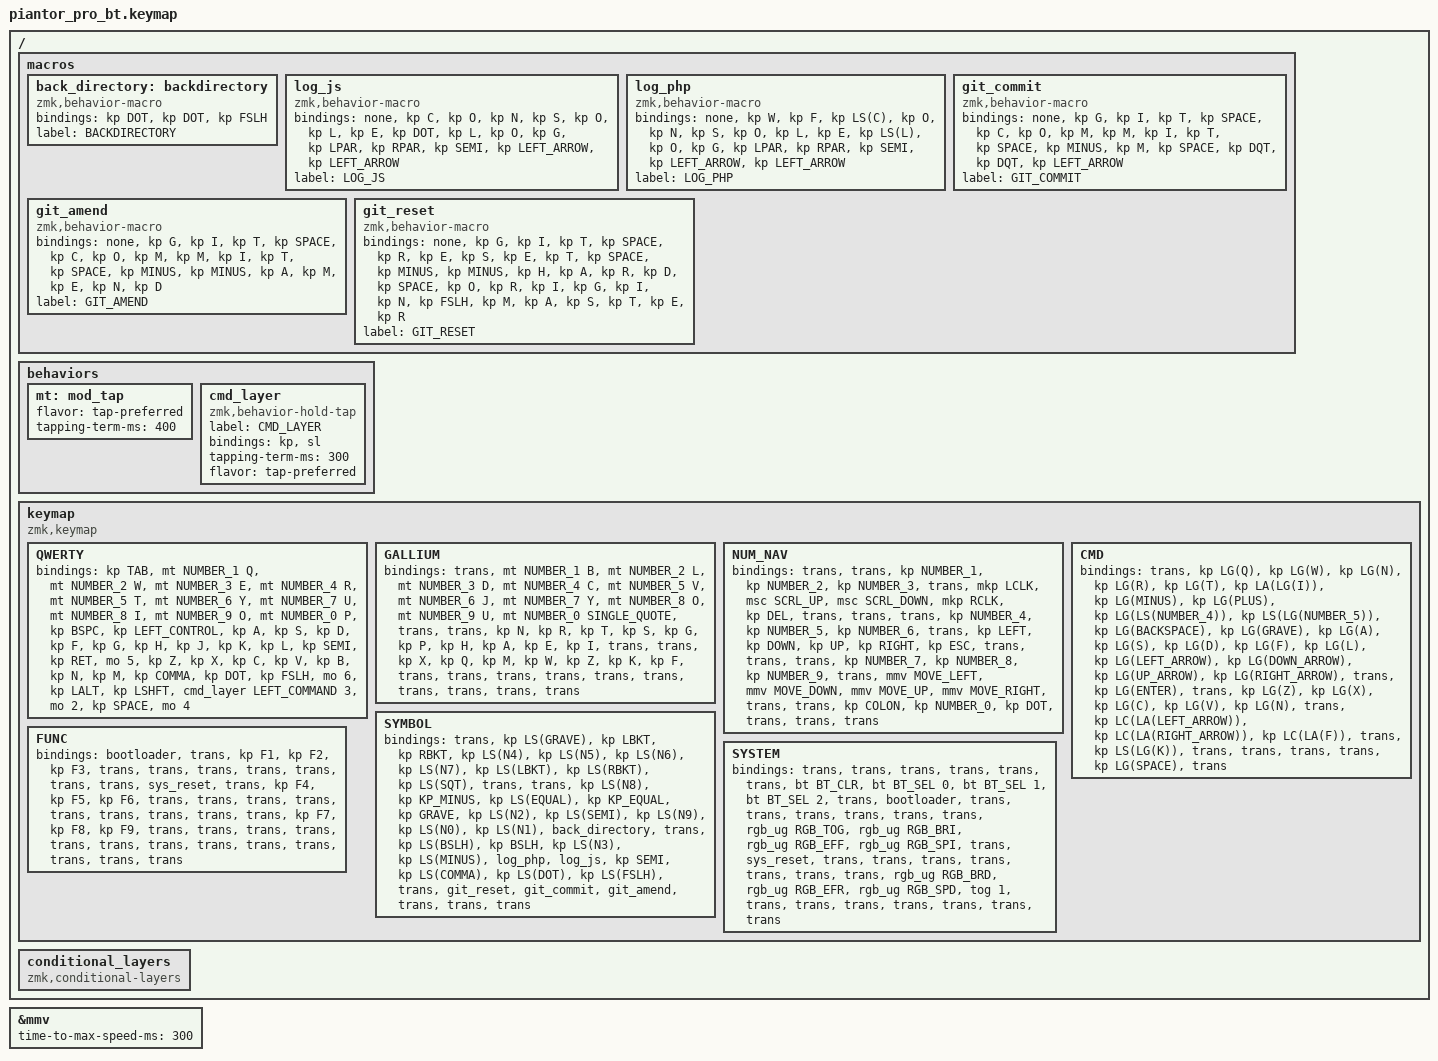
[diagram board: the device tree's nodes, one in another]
#define ZMK_POINTING_DEFAULT_MOVE_VAL 1500
#define ZMK_POINTING_DEFAULT_SCRL_VAL 15

#include <dt-bindings/zmk/behaviors.h>
#include <behaviors.dtsi>
#include <dt-bindings/zmk/bt.h>
#include <dt-bindings/zmk/keys.h>
#include <dt-bindings/zmk/pointing.h>
#include <dt-bindings/zmk/rgb.h>

&mt {
    tapping-term-ms = <400>;
    flavor = "tap-preferred";
};

&mmv { time-to-max-speed-ms = <300>; };

/ {
    macros {
        back_directory: backdirectory {
            compatible = "zmk,behavior-macro";
            #binding-cells = <0>;
            bindings = <&kp DOT &kp DOT &kp FSLH>;
            label = "BACKDIRECTORY";
        };

        log_js: log_js {
            compatible = "zmk,behavior-macro";
            #binding-cells = <0>;
            bindings = <&none &kp C &kp O &kp N &kp S &kp O &kp L &kp E &kp DOT &kp L &kp O &kp G &kp LPAR &kp RPAR &kp SEMI &kp LEFT_ARROW &kp LEFT_ARROW>;
            label = "LOG_JS";
        };

        log_php: log_php {
            compatible = "zmk,behavior-macro";
            #binding-cells = <0>;
            bindings = <&none &kp W &kp F &kp LS(C) &kp O &kp N &kp S &kp O &kp L &kp E &kp LS(L) &kp O &kp G &kp LPAR &kp RPAR &kp SEMI &kp LEFT_ARROW &kp LEFT_ARROW>;
            label = "LOG_PHP";
        };

        git_commit: git_commit {
            compatible = "zmk,behavior-macro";
            #binding-cells = <0>;
            bindings = <&none &kp G &kp I &kp T &kp SPACE &kp C &kp O &kp M &kp M &kp I &kp T &kp SPACE &kp MINUS &kp M &kp SPACE &kp DQT &kp DQT &kp LEFT_ARROW>;
            label = "GIT_COMMIT";
        };

        git_amend: git_amend {
            compatible = "zmk,behavior-macro";
            #binding-cells = <0>;
            bindings = <&none &kp G &kp I &kp T &kp SPACE &kp C &kp O &kp M &kp M &kp I &kp T &kp SPACE &kp MINUS &kp MINUS &kp A &kp M &kp E &kp N &kp D>;
            label = "GIT_AMEND";
        };

        git_reset: git_reset {
            compatible = "zmk,behavior-macro";
            #binding-cells = <0>;
            bindings = <&none &kp G &kp I &kp T &kp SPACE &kp R &kp E &kp S &kp E &kp T &kp SPACE &kp MINUS &kp MINUS &kp H &kp A &kp R &kp D &kp SPACE &kp O &kp R &kp I &kp G &kp I &kp N &kp FSLH &kp M &kp A &kp S &kp T &kp E &kp R>;
            label = "GIT_RESET";
        };
    };

    behaviors {
        mt: mod_tap {
            flavor = "tap-preferred";
            tapping-term-ms = <400>;
        };

        cmd_layer: cmd_layer {
            compatible = "zmk,behavior-hold-tap";
            label = "CMD_LAYER";
            bindings = <&kp>, <&sl>;

            #binding-cells = <2>;
            tapping-term-ms = <300>;
            flavor = "tap-preferred";
        };
    };

    keymap {
        compatible = "zmk,keymap";

        QWERTY {
            bindings = <
&kp TAB  &mt NUMBER_1 Q  &mt NUMBER_2 W  &mt NUMBER_3 E  &mt NUMBER_4 R  &mt NUMBER_5 T  &mt NUMBER_6 Y  &mt NUMBER_7 U  &mt NUMBER_8 I  &mt NUMBER_9 O  &mt NUMBER_0 P  &kp BSPC  &kp LEFT_CONTROL  &kp A  &kp S  &kp D  &kp F  &kp G  &kp H  &kp J  &kp K  &kp L  &kp SEMI  &kp RET  &mo 5  &kp Z  &kp X  &kp C  &kp V  &kp B  &kp N  &kp M  &kp COMMA  &kp DOT  &kp FSLH  &mo 6  &kp LALT  &kp LSHFT  &cmd_layer LEFT_COMMAND 3  &mo 2  &kp SPACE  &mo 4
            >;
        };

        GALLIUM {
            bindings = <
&trans  &mt NUMBER_1 B  &mt NUMBER_2 L  &mt NUMBER_3 D  &mt NUMBER_4 C  &mt NUMBER_5 V  &mt NUMBER_6 J  &mt NUMBER_7 Y  &mt NUMBER_8 O  &mt NUMBER_9 U  &mt NUMBER_0 SINGLE_QUOTE  &trans  &trans  &kp N  &kp R  &kp T  &kp S  &kp G  &kp P  &kp H  &kp A  &kp E  &kp I  &trans  &trans  &kp X  &kp Q  &kp M  &kp W  &kp Z  &kp K  &kp F  &trans  &trans  &trans  &trans  &trans  &trans  &trans  &trans  &trans  &trans
            >;
        };

        NUM_NAV {
            bindings = <
&trans  &trans  &kp NUMBER_1  &kp NUMBER_2  &kp NUMBER_3  &trans  &mkp LCLK  &msc SCRL_UP  &msc SCRL_DOWN  &mkp RCLK  &kp DEL  &trans  &trans  &trans  &kp NUMBER_4  &kp NUMBER_5  &kp NUMBER_6  &trans  &kp LEFT  &kp DOWN  &kp UP  &kp RIGHT  &kp ESC  &trans  &trans  &trans  &kp NUMBER_7  &kp NUMBER_8  &kp NUMBER_9  &trans  &mmv MOVE_LEFT  &mmv MOVE_DOWN  &mmv MOVE_UP  &mmv MOVE_RIGHT  &trans  &trans  &kp COLON  &kp NUMBER_0  &kp DOT  &trans  &trans  &trans
            >;
        };

        CMD {
            bindings = <
&trans  &kp LG(Q)  &kp LG(W)  &kp LG(N)  &kp LG(R)  &kp LG(T)  &kp LA(LG(I))  &kp LG(MINUS)  &kp LG(PLUS)  &kp LG(LS(NUMBER_4))  &kp LS(LG(NUMBER_5))  &kp LG(BACKSPACE)  &kp LG(GRAVE)  &kp LG(A)  &kp LG(S)  &kp LG(D)  &kp LG(F)  &kp LG(L)  &kp LG(LEFT_ARROW)  &kp LG(DOWN_ARROW)  &kp LG(UP_ARROW)  &kp LG(RIGHT_ARROW)  &trans  &kp LG(ENTER)  &trans  &kp LG(Z)  &kp LG(X)  &kp LG(C)  &kp LG(V)  &kp LG(N)  &trans  &kp LC(LA(LEFT_ARROW))  &kp LC(LA(RIGHT_ARROW))  &kp LC(LA(F))  &trans  &kp LS(LG(K))  &trans  &trans  &trans  &trans  &kp LG(SPACE)  &trans
            >;
        };

        SYMBOL {
            bindings = <
&trans  &kp LS(GRAVE)  &kp LBKT  &kp RBKT  &kp LS(N4)  &kp LS(N5)  &kp LS(N6)  &kp LS(N7)  &kp LS(LBKT)  &kp LS(RBKT)  &kp LS(SQT)  &trans  &trans  &kp LS(N8)  &kp KP_MINUS  &kp LS(EQUAL)  &kp KP_EQUAL  &kp GRAVE  &kp LS(N2)  &kp LS(SEMI)  &kp LS(N9)  &kp LS(N0)  &kp LS(N1)  &back_directory  &trans  &kp LS(BSLH)  &kp BSLH  &kp LS(N3)  &kp LS(MINUS)  &log_php  &log_js  &kp SEMI  &kp LS(COMMA)  &kp LS(DOT)  &kp LS(FSLH)  &trans  &git_reset  &git_commit  &git_amend  &trans  &trans  &trans
            >;
        };

        FUNC {
            bindings = <
&bootloader  &trans  &kp F1  &kp F2  &kp F3  &trans  &trans  &trans  &trans  &trans  &trans  &trans  &sys_reset  &trans  &kp F4  &kp F5  &kp F6  &trans  &trans  &trans  &trans  &trans  &trans  &trans  &trans  &trans  &kp F7  &kp F8  &kp F9  &trans  &trans  &trans  &trans  &trans  &trans  &trans  &trans  &trans  &trans  &trans  &trans  &trans
            >;
        };

        SYSTEM {
            bindings = <
&trans  &trans  &trans  &trans  &trans  &trans  &bt BT_CLR  &bt BT_SEL 0  &bt BT_SEL 1  &bt BT_SEL 2  &trans  &bootloader  &trans  &trans  &trans  &trans  &trans  &trans  &rgb_ug RGB_TOG  &rgb_ug RGB_BRI  &rgb_ug RGB_EFF  &rgb_ug RGB_SPI  &trans  &sys_reset  &trans  &trans  &trans  &trans  &trans  &trans  &trans  &rgb_ug RGB_BRD  &rgb_ug RGB_EFR  &rgb_ug RGB_SPD  &tog 1  &trans  &trans  &trans  &trans  &trans  &trans  &trans
            >;
        };
    };

    conditional_layers { compatible = "zmk,conditional-layers"; };
};
